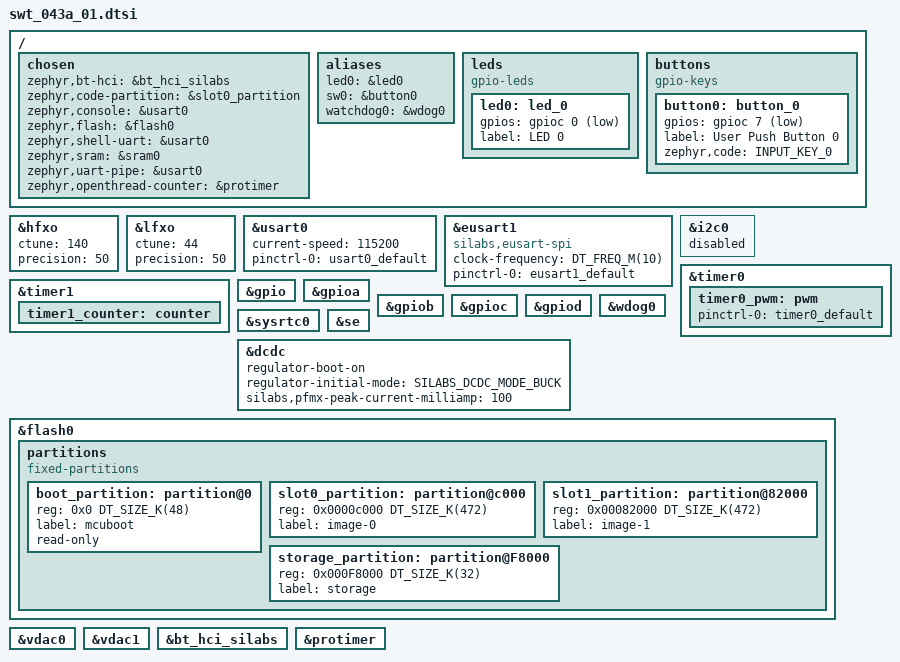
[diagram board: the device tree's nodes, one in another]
#include <silabs/xg24/clock-lfxo.dtsi>
#include <zephyr/dt-bindings/input/input-event-codes.h>
#include <zephyr/dt-bindings/pwm/pwm.h>
#include <zephyr/dt-bindings/regulator/silabs_dcdc.h>

#include "swt_043a_01-pinctrl.dtsi"
#include "swt_043a_01-hfrcodpll.dtsi"

/ {
	chosen {
		zephyr,bt-hci = &bt_hci_silabs;
		zephyr,code-partition = &slot0_partition;
		zephyr,console = &usart0;
		zephyr,flash = &flash0;
		zephyr,shell-uart = &usart0;
		zephyr,sram = &sram0;
		zephyr,uart-pipe = &usart0;
		zephyr,openthread-counter = &protimer;
	};

	/* These aliases are provided for compatibility with samples */
	aliases {
		led0 = &led0;
		sw0 = &button0;
		watchdog0 = &wdog0;
	};

	leds {
		compatible = "gpio-leds";

		led0: led_0 {
			gpios = <&gpioc 0 GPIO_ACTIVE_LOW>;
			label = "LED 0";
		};
	};

	buttons {
		compatible = "gpio-keys";

		button0: button_0 {
			gpios = <&gpioc 7 GPIO_ACTIVE_LOW>;
			label = "User Push Button 0";
			zephyr,code = <INPUT_KEY_0>;
		};
	};
};

&hfxo {
	ctune = <140>;
	precision = <50>;
	status = "okay";
};

&lfxo {
	ctune = <44>;
	precision = <50>;
	status = "okay";
};

&usart0 {
	current-speed = <115200>;
	pinctrl-0 = <&usart0_default>;
	pinctrl-names = "default";
	status = "okay";
};

&eusart1 {
	compatible = "silabs,eusart-spi";
	#address-cells = <1>;
	#size-cells = <0>;
	clock-frequency = <DT_FREQ_M(10)>;
	pinctrl-0 = <&eusart1_default>;
	pinctrl-names = "default";
	status = "okay";
};

&i2c0 {
	status = "disabled";
};

&timer0 {
	status = "okay";

	timer0_pwm: pwm {
		pinctrl-0 = <&timer0_default>;
		pinctrl-names = "default";
		status = "okay";
	};
};

&timer1 {
	status = "okay";

	timer1_counter: counter {
		status = "okay";
	};
};

&gpio {
	status = "okay";
};

&gpioa {
	status = "okay";
};

&gpiob {
	status = "okay";
};

&gpioc {
	status = "okay";
};

&gpiod {
	status = "okay";
};

&wdog0 {
	status = "okay";
};

&sysrtc0 {
	status = "okay";
};

&se {
	status = "okay";
};

&dcdc {
	regulator-boot-on;
	regulator-initial-mode = <SILABS_DCDC_MODE_BUCK>;
	silabs,pfmx-peak-current-milliamp = <100>;
	status = "okay";
};

&flash0 {
	partitions {
		compatible = "fixed-partitions";
		#address-cells = <1>;
		#size-cells = <1>;

		/* Reserve 48 kB for the bootloader */
		boot_partition: partition@0 {
			reg = <0x0 DT_SIZE_K(48)>;
			label = "mcuboot";
			read-only;
		};

		/* Reserve 472 kB for the application in slot 0 */
		slot0_partition: partition@c000 {
			reg = <0x0000c000 DT_SIZE_K(472)>;
			label = "image-0";
		};

		/* Reserve 472 kB for the application in slot 1 */
		slot1_partition: partition@82000 {
			reg = <0x00082000 DT_SIZE_K(472)>;
			label = "image-1";
		};

		/* Set 32 kB of storage at the end of the 1536 kB of flash */
		storage_partition: partition@F8000 {
			reg = <0x000F8000 DT_SIZE_K(32)>;
			label = "storage";
		};
	};
};

&vdac0 {
	status = "okay";
};

&vdac1 {
	status = "okay";
};

&bt_hci_silabs {
	status = "okay";
};

&protimer {
	status = "okay";
};
